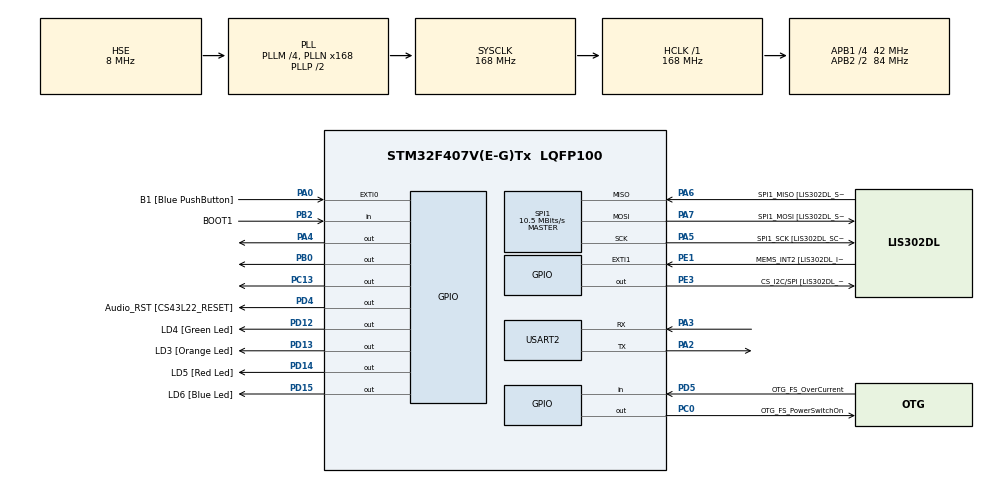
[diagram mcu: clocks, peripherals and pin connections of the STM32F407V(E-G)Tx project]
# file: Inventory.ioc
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Mcu.Family=STM32F4
Mcu.Name=STM32F407V(E-G)Tx
Mcu.Package=LQFP100
NVIC.PriorityGroup=NVIC_PRIORITYGROUP_0
NVIC.USART2_IRQn=true\:0\:0\:false\:false\:true\:true\:true\:true
PA0-WKUP.GPIO_Label=B1 [Blue PushButton]
PA0-WKUP.Signal=GPXTI0
PA10.GPIO_Label=OTG_FS_ID
PA10.GPIO_Mode=GPIO_MODE_AF_PP
PA10.GPIO_PuPd=GPIO_NOPULL
PA10.GPIO_Speed=GPIO_SPEED_FREQ_LOW
PA10.Signal=USB_OTG_FS_ID
PA11.GPIO_Label=OTG_FS_DM
PA11.GPIO_Mode=GPIO_MODE_AF_PP
PA11.GPIO_PuPd=GPIO_NOPULL
PA11.GPIO_Speed=GPIO_SPEED_FREQ_LOW
PA11.Signal=USB_OTG_FS_DM
PA12.GPIO_Label=OTG_FS_DP
PA12.GPIO_Mode=GPIO_MODE_AF_PP
PA12.GPIO_PuPd=GPIO_NOPULL
PA12.GPIO_Speed=GPIO_SPEED_FREQ_LOW
PA12.Signal=USB_OTG_FS_DP
PA13.GPIO_Label=SWDIO
PA13.Mode=Serial_Wire
PA13.Signal=SYS_JTMS-SWDIO
PA14.GPIO_Label=SWCLK
PA14.Mode=Serial_Wire
PA14.Signal=SYS_JTCK-SWCLK
PA2.Mode=Asynchronous
PA2.Signal=USART2_TX
PA3.Mode=Asynchronous
PA3.Signal=USART2_RX
PA4.Signal=GPIO_Output
PA5.GPIO_Label=SPI1_SCK [LIS302DL_SCL/SPC]
PA5.GPIO_Mode=GPIO_MODE_AF_PP
PA5.GPIO_PuPd=GPIO_NOPULL
PA5.GPIO_Speed=GPIO_SPEED_FREQ_LOW
PA5.Mode=Full_Duplex_Master
PA5.Signal=SPI1_SCK
PA6.GPIO_Label=SPI1_MISO [LIS302DL_SDO]
PA6.GPIO_Mode=GPIO_MODE_AF_PP
PA6.GPIO_PuPd=GPIO_NOPULL
PA6.GPIO_Speed=GPIO_SPEED_FREQ_LOW
PA6.Mode=Full_Duplex_Master
PA6.Signal=SPI1_MISO
PA7.GPIO_Label=SPI1_MOSI [LIS302DL_SDA/SDI/SDO]
PA7.GPIO_Mode=GPIO_MODE_AF_PP
PA7.GPIO_PuPd=GPIO_NOPULL
PA7.GPIO_Speed=GPIO_SPEED_FREQ_LOW
PA7.Mode=Full_Duplex_Master
PA7.Signal=SPI1_MOSI
PA9.GPIO_Label=VBUS_FS
PA9.GPIO_Mode=GPIO_MODE_INPUT
PA9.GPIO_PuPd=GPIO_NOPULL
PA9.Signal=USB_OTG_FS_VBUS
PB0.Signal=GPIO_Output
PB10.GPIO_Label=CLK_IN [MP45DT02_CLK]
PB10.GPIO_Mode=GPIO_MODE_AF_PP
PB10.GPIO_PuPd=GPIO_NOPULL
PB10.GPIO_Speed=GPIO_SPEED_FREQ_LOW
PB10.Signal=I2S2_CK
PB2.GPIO_Label=BOOT1
PB2.GPIO_Mode=GPIO_MODE_INPUT
PB2.GPIO_PuPd=GPIO_NOPULL
PB2.Signal=GPIO_Input
PB3.GPIO_Label=SWO
PB3.Signal=SYS_JTDO-SWO
PB6.GPIO_Label=Audio_SCL [CS43L22_SCL]
PB6.GPIO_Mode=GPIO_MODE_AF_OD
PB6.GPIO_PuPd=GPIO_NOPULL
PB6.GPIO_Speed=GPIO_SPEED_FREQ_LOW
PB6.Signal=I2C1_SCL
PB9.GPIO_Label=Audio_SDA [CS43L22_SDA]
PB9.GPIO_Mode=GPIO_MODE_AF_OD
PB9.GPIO_PuPd=GPIO_NOPULL
PB9.GPIO_Speed=GPIO_SPEED_FREQ_LOW
PB9.Signal=I2C1_SDA
PC0.GPIO_Label=OTG_FS_PowerSwitchOn
PC0.GPIO_PuPd=GPIO_NOPULL
PC0.GPIO_Speed=GPIO_SPEED_FREQ_LOW
PC0.PinState=GPIO_PIN_SET
PC0.Signal=GPIO_Output
PC10.GPIO_Label=I2S3_SCK [CS43L22_SCLK]
PC10.GPIO_Mode=GPIO_MODE_AF_PP
PC10.GPIO_PuPd=GPIO_NOPULL
PC10.GPIO_Speed=GPIO_SPEED_FREQ_LOW
PC10.Signal=I2S3_CK
PC12.GPIO_Label=I2S3_SD [CS43L22_SDIN]
PC12.GPIO_Mode=GPIO_MODE_AF_PP
PC12.GPIO_PuPd=GPIO_NOPULL
PC12.GPIO_Speed=GPIO_SPEED_FREQ_LOW
PC12.Signal=I2S3_SD
PC13-ANTI_TAMP.Signal=GPIO_Output
PC14-OSC32_IN.GPIO_Label=PC14-OSC32_IN
PC14-OSC32_IN.Signal=RCC_OSC32_IN
PC15-OSC32_OUT.GPIO_Label=PC15-OSC32_OUT
PC15-OSC32_OUT.Signal=RCC_OSC32_OUT
PC3.GPIO_Label=PDM_OUT [MP45DT02_DOUT]
PC3.GPIO_Mode=GPIO_MODE_AF_PP
PC3.GPIO_PuPd=GPIO_NOPULL
PC3.GPIO_Speed=GPIO_SPEED_FREQ_LOW
PC3.Signal=I2S2_SD
PC7.GPIO_Label=I2S3_MCK [CS43L22_MCLK]
PC7.GPIO_Mode=GPIO_MODE_AF_PP
PC7.GPIO_PuPd=GPIO_NOPULL
PC7.GPIO_Speed=GPIO_SPEED_FREQ_LOW
PC7.Signal=I2S3_MCK
PD12.GPIO_Label=LD4 [Green Led]
PD12.GPIO_PuPd=GPIO_NOPULL
PD12.GPIO_Speed=GPIO_SPEED_FREQ_LOW
PD12.Signal=GPIO_Output
PD13.GPIO_Label=LD3 [Orange Led]
PD13.GPIO_PuPd=GPIO_NOPULL
PD13.GPIO_Speed=GPIO_SPEED_FREQ_LOW
PD13.Signal=GPIO_Output
PD14.GPIO_Label=LD5 [Red Led]
PD14.GPIO_PuPd=GPIO_NOPULL
PD14.GPIO_Speed=GPIO_SPEED_FREQ_LOW
PD14.Signal=GPIO_Output
PD15.GPIO_Label=LD6 [Blue Led]
PD15.GPIO_PuPd=GPIO_NOPULL
PD15.GPIO_Speed=GPIO_SPEED_FREQ_LOW
PD15.Signal=GPIO_Output
PD4.GPIO_Label=Audio_RST [CS43L22_RESET]
PD4.GPIO_PuPd=GPIO_NOPULL
PD4.GPIO_Speed=GPIO_SPEED_FREQ_LOW
PD4.Signal=GPIO_Output
PD5.GPIO_Label=OTG_FS_OverCurrent
PD5.GPIO_Mode=GPIO_MODE_INPUT
PD5.GPIO_PuPd=GPIO_NOPULL
PD5.Signal=GPIO_Input
PE1.GPIO_Label=MEMS_INT2 [LIS302DL_INT2]
PE1.GPIO_ModeDefaultEXTI=GPIO_MODE_EVT_RISING
PE1.GPIO_PuPd=GPIO_NOPULL
PE1.Signal=GPXTI1
PE3.GPIO_Label=CS_I2C/SPI [LIS302DL_CS_I2C/SPI]
PE3.GPIO_PuPd=GPIO_NOPULL
PE3.GPIO_Speed=GPIO_SPEED_FREQ_LOW
PE3.Signal=GPIO_Output
PH0-OSC_IN.GPIO_Label=PH0-OSC_IN
PH0-OSC_IN.Mode=HSE-External-Oscillator
PH0-OSC_IN.Signal=RCC_OSC_IN
PH1-OSC_OUT.GPIO_Label=PH1-OSC_OUT
PH1-OSC_OUT.Mode=HSE-External-Oscillator
PH1-OSC_OUT.Signal=RCC_OSC_OUT
ProjectManager.HeapSize=0x800
ProjectManager.StackSize=0x800
ProjectManager.TargetToolchain=STM32CubeIDE
RCC.48MHZClocksFreq_Value=48000000
RCC.AHBFreq_Value=168000000
RCC.APB1CLKDivider=RCC_HCLK_DIV4
RCC.APB1Freq_Value=42000000
RCC.APB1TimFreq_Value=84000000
RCC.APB2CLKDivider=RCC_HCLK_DIV2
RCC.APB2Freq_Value=84000000
RCC.APB2TimFreq_Value=168000000
RCC.CortexFreq_Value=168000000
RCC.HCLKFreq_Value=168000000
RCC.HSE_VALUE=8000000
RCC.HSI_VALUE=16000000
RCC.LSE_VALUE=32768
RCC.PLLM=4
RCC.PLLN=168
RCC.PLLP=2
RCC.PLLQ=7
RCC.PLLSourceVirtual=RCC_PLLSOURCE_HSE
RCC.SYSCLKFreq_VALUE=168000000
RCC.SYSCLKSource=RCC_SYSCLKSOURCE_PLLCLK
RCC.VCOOutputFreq_Value=336000000
SPI1.BaudRatePrescaler=SPI_BAUDRATEPRESCALER_8
SPI1.CalculateBaudRate=10.5 MBits/s
SPI1.Direction=SPI_DIRECTION_2LINES
SPI1.Mode=SPI_MODE_MASTER
SPI1.VirtualType=VM_MASTER
STMicroelectronics.X-CUBE-AI.8.1.0.ActivationBufferSizeList=2488224
STMicroelectronics.X-CUBE-AI.8.1.0.ActivationBuffers=(ai_handle) 0x00000000
STMicroelectronics.X-CUBE-AI.8.1.0.ActivationPragmas=AI_CUSTOM
STMicroelectronics.X-CUBE-AI.8.1.0.HeapSize=0x800
STMicroelectronics.X-CUBE-AI.8.1.0.InternalRamActivationBufferMaxSize=AI_NETWORK_9_DATA_ACTIVATIONS_SIZE
STMicroelectronics.X-CUBE-AI.8.1.0.LatestDirectoryUsed-e215b0f68a62c3eeb1ee8877ed58282e5802af02ffe05f54a25cac139fafb503=C\:\\Users\\user\\Desktop\\IOT
STMicroelectronics.X-CUBE-AI.8.1.0.MaximumNumberOfInputLayer=1
STMicroelectronics.X-CUBE-AI.8.1.0.MaximumNumberOfOutputLayer=1
STMicroelectronics.X-CUBE-AI.8.1.0.MaximumSizeOfInputLayer=1
STMicroelectronics.X-CUBE-AI.8.1.0.MaximumSizeOfOutputLayer=1
STMicroelectronics.X-CUBE-AI.8.1.0.ModelActualCompression-e215b0f68a62c3eeb1ee8877ed58282e5802af02ffe05f54a25cac139fafb503=0.0
STMicroelectronics.X-CUBE-AI.8.1.0.ModelCompression-e215b0f68a62c3eeb1ee8877ed58282e5802af02ffe05f54a25cac139fafb503=None
STMicroelectronics.X-CUBE-AI.8.1.0.ModelFlashOccupation-e215b0f68a62c3eeb1ee8877ed58282e5802af02ffe05f54a25cac139fafb503=2128442
STMicroelectronics.X-CUBE-AI.8.1.0.ModelHashList=e215b0f68a62c3eeb1ee8877ed58282e5802af02ffe05f54a25cac139fafb503
STMicroelectronics.X-CUBE-AI.8.1.0.ModelKind-e215b0f68a62c3eeb1ee8877ed58282e5802af02ffe05f54a25cac139fafb503=KERAS
STMicroelectronics.X-CUBE-AI.8.1.0.ModelMacc-e215b0f68a62c3eeb1ee8877ed58282e5802af02ffe05f54a25cac139fafb503=63536066
STMicroelectronics.X-CUBE-AI.8.1.0.ModelName-e215b0f68a62c3eeb1ee8877ed58282e5802af02ffe05f54a25cac139fafb503=network_9
STMicroelectronics.X-CUBE-AI.8.1.0.ModelNameList=network_9
STMicroelectronics.X-CUBE-AI.8.1.0.ModelRamOccupation-e215b0f68a62c3eeb1ee8877ed58282e5802af02ffe05f54a25cac139fafb503=2488224
STMicroelectronics.X-CUBE-AI.8.1.0.ModelStructureFile-e215b0f68a62c3eeb1ee8877ed58282e5802af02ffe05f54a25cac139fafb503=C\:\\Users\\user\\Desktop\\IOT\\keras_model.h5
STMicroelectronics.X-CUBE-AI.8.1.0.ModelType-e215b0f68a62c3eeb1ee8877ed58282e5802af02ffe05f54a25cac139fafb503=Saved model
STMicroelectronics.X-CUBE-AI.8.1.0.ReadyForCodeGeneration=true
STMicroelectronics.X-CUBE-AI.8.1.0.StackSize=0x800
STMicroelectronics.X-CUBE-AI.8.1.0.WorkingBufferStartAddrList=0xFFFFFFFF
STMicroelectronics.X-CUBE-AI.8.1.0.XAaCUBEAaAICcArtificialOoIntelligenceJjCore=true
STMicroelectronics.X-CUBE-AI.8.1.0.copyWeightToRam=false
STMicroelectronics.X-CUBE-AI.8.1.0.copyWeightToRam-e215b0f68a62c3eeb1ee8877ed58282e5802af02ffe05f54a25cac139fafb503=false
STMicroelectronics.X-CUBE-AI.8.1.0.customLayerConfigEnabled=false
STMicroelectronics.X-CUBE-AI.8.1.0.customLayerConfigEnabled-e215b0f68a62c3eeb1ee8877ed58282e5802af02ffe05f54a25cac139fafb503=false
STMicroelectronics.X-CUBE-AI.8.1.0.memoryPool0driver-e215b0f68a62c3eeb1ee8877ed58282e5802af02ffe05f54a25cac139fafb503=RAM
STMicroelectronics.X-CUBE-AI.8.1.0.memoryPool0id-e215b0f68a62c3eeb1ee8877ed58282e5802af02ffe05f54a25cac139fafb503=-1
STMicroelectronics.X-CUBE-AI.8.1.0.memoryPool0max-e215b0f68a62c3eeb1ee8877ed58282e5802af02ffe05f54a25cac139fafb503=112
STMicroelectronics.X-CUBE-AI.8.1.0.memoryPool0name-e215b0f68a62c3eeb1ee8877ed58282e5802af02ffe05f54a25cac139fafb503=pool1
STMicroelectronics.X-CUBE-AI.8.1.0.memoryPool0size-e215b0f68a62c3eeb1ee8877ed58282e5802af02ffe05f54a25cac139fafb503=112
STMicroelectronics.X-CUBE-AI.8.1.0.memoryPool0start-e215b0f68a62c3eeb1ee8877ed58282e5802af02ffe05f54a25cac139fafb503=Auto
STMicroelectronics.X-CUBE-AI.8.1.0.memoryPool0used-e215b0f68a62c3eeb1ee8877ed58282e5802af02ffe05f54a25cac139fafb503=0.0
STMicroelectronics.X-CUBE-AI.8.1.0.memoryPool1driver-e215b0f68a62c3eeb1ee8877ed58282e5802af02ffe05f54a25cac139fafb503=RAM2
STMicroelectronics.X-CUBE-AI.8.1.0.memoryPool1id-e215b0f68a62c3eeb1ee8877ed58282e5802af02ffe05f54a25cac139fafb503=-1
STMicroelectronics.X-CUBE-AI.8.1.0.memoryPool1max-e215b0f68a62c3eeb1ee8877ed58282e5802af02ffe05f54a25cac139fafb503=16
STMicroelectronics.X-CUBE-AI.8.1.0.memoryPool1name-e215b0f68a62c3eeb1ee8877ed58282e5802af02ffe05f54a25cac139fafb503=pool2
STMicroelectronics.X-CUBE-AI.8.1.0.memoryPool1size-e215b0f68a62c3eeb1ee8877ed58282e5802af02ffe05f54a25cac139fafb503=16
STMicroelectronics.X-CUBE-AI.8.1.0.memoryPool1start-e215b0f68a62c3eeb1ee8877ed58282e5802af02ffe05f54a25cac139fafb503=Auto
STMicroelectronics.X-CUBE-AI.8.1.0.memoryPool1used-e215b0f68a62c3eeb1ee8877ed58282e5802af02ffe05f54a25cac139fafb503=0.0
STMicroelectronics.X-CUBE-AI.8.1.0.memoryPool2driver-e215b0f68a62c3eeb1ee8877ed58282e5802af02ffe05f54a25cac139fafb503=CCMRAM
STMicroelectronics.X-CUBE-AI.8.1.0.memoryPool2id-e215b0f68a62c3eeb1ee8877ed58282e5802af02ffe05f54a25cac139fafb503=-1
STMicroelectronics.X-CUBE-AI.8.1.0.memoryPool2max-e215b0f68a62c3eeb1ee8877ed58282e5802af02ffe05f54a25cac139fafb503=64
STMicroelectronics.X-CUBE-AI.8.1.0.memoryPool2name-e215b0f68a62c3eeb1ee8877ed58282e5802af02ffe05f54a25cac139fafb503=pool3
STMicroelectronics.X-CUBE-AI.8.1.0.memoryPool2size-e215b0f68a62c3eeb1ee8877ed58282e5802af02ffe05f54a25cac139fafb503=64
STMicroelectronics.X-CUBE-AI.8.1.0.memoryPool2start-e215b0f68a62c3eeb1ee8877ed58282e5802af02ffe05f54a25cac139fafb503=Auto
STMicroelectronics.X-CUBE-AI.8.1.0.memoryPool2used-e215b0f68a62c3eeb1ee8877ed58282e5802af02ffe05f54a25cac139fafb503=0.0
STMicroelectronics.X-CUBE-AI.8.1.0.memoryPool3driver-e215b0f68a62c3eeb1ee8877ed58282e5802af02ffe05f54a25cac139fafb503=Custom
STMicroelectronics.X-CUBE-AI.8.1.0.memoryPool3id-e215b0f68a62c3eeb1ee8877ed58282e5802af02ffe05f54a25cac139fafb503=0
STMicroelectronics.X-CUBE-AI.8.1.0.memoryPool3max-e215b0f68a62c3eeb1ee8877ed58282e5802af02ffe05f54a25cac139fafb503=2147483647
STMicroelectronics.X-CUBE-AI.8.1.0.memoryPool3name-e215b0f68a62c3eeb1ee8877ed58282e5802af02ffe05f54a25cac139fafb503=pool4
STMicroelectronics.X-CUBE-AI.8.1.0.memoryPool3size-e215b0f68a62c3eeb1ee8877ed58282e5802af02ffe05f54a25cac139fafb503=0
STMicroelectronics.X-CUBE-AI.8.1.0.memoryPool3start-e215b0f68a62c3eeb1ee8877ed58282e5802af02ffe05f54a25cac139fafb503=0x00000000
STMicroelectronics.X-CUBE-AI.8.1.0.memoryPool3used-e215b0f68a62c3eeb1ee8877ed58282e5802af02ffe05f54a25cac139fafb503=2458816.0
STMicroelectronics.X-CUBE-AI.8.1.0.noOnnxIoTranspose=false
STMicroelectronics.X-CUBE-AI.8.1.0.noOnnxIoTranspose-e215b0f68a62c3eeb1ee8877ed58282e5802af02ffe05f54a25cac139fafb503=false
STMicroelectronics.X-CUBE-AI.8.1.0.splitWeigths-e215b0f68a62c3eeb1ee8877ed58282e5802af02ffe05f54a25cac139fafb503=true
STMicroelectronics.X-CUBE-AI.8.1.0.useInputAllocation=true
STMicroelectronics.X-CUBE-AI.8.1.0.useInputAllocation-e215b0f68a62c3eeb1ee8877ed58282e5802af02ffe05f54a25cac139fafb503=true
STMicroelectronics.X-CUBE-AI.8.1.0.useOutputAllocation=true
STMicroelectronics.X-CUBE-AI.8.1.0.useOutputAllocation-e215b0f68a62c3eeb1ee8877ed58282e5802af02ffe05f54a25cac139fafb503=true
USART2.VirtualMode=VM_ASYNC
VP_CRC_VS_CRC.Mode=CRC_Activate
VP_STMicroelectronics.X-CUBE-AI_VS_ArtificialOoIntelligenceJjXAaCUBEAaAI_8.1.0_8.1.0.Mode=ArtificialOoIntelligenceJjXAaCUBEAaAI
board=STM32F407G-DISC1

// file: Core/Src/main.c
/* USER CODE BEGIN Header */
/**
  ******************************************************************************
  * @file           : main.c
  * @brief          : Main program body
  ******************************************************************************
  * @attention
  *
  * Copyright (c) 2024 STMicroelectronics.
  * All rights reserved.
  *
  * This software is licensed under terms that can be found in the LICENSE file
  * in the root directory of this software component.
  * If no LICENSE file comes with this software, it is provided AS-IS.
  *
  ******************************************************************************
  */
/* USER CODE END Header */
#include "main.h"
#include "stdlib.h"
#include "ai_platform.h"
#include "ai_datatypes_defines.h"
#include "network_9_data_params.h"
#include "network_9_data.h"
#include "network_9_config.h"
#include "network_9.h"

/* USER CODE BEGIN Includes */
#include "rc522.h"
#include "string.h"
#include "stdio.h"
#include "stdint.h"
#include "errno.h"

/* USER CODE END Includes */

CRC_HandleTypeDef hcrc;

SPI_HandleTypeDef hspi1;

UART_HandleTypeDef huart2;

/* USER CODE BEGIN PV */
#define UNREAL_RFID_DATA "ABCDE"
#define RFID_DATA_SIZE 5
#define CLASSIFICATION_RESULT_SIZE 20
char out_data[CLASSIFICATION_RESULT_SIZE];
ai_handle network_9 = AI_HANDLE_NULL;
ai_buffer ai_input[AI_NETWORK_9_IN_NUM]; // Declare ai_input
ai_buffer ai_output[AI_NETWORK_9_OUT_NUM]; // Declare ai_output
void SystemClock_Config(void);
static void MX_GPIO_Init(void);
static void MX_CRC_Init(void);
static void MX_SPI1_Init(void);
static void MX_USART2_UART_Init(void);
void send_data_to_nodemcu(uint8_t* rfid_data, char* classification_results);
void classify_image(const float* input_image_data, ai_handle network_handle);
float* read_image_file(const char* filename);

int main(void) {
    uint8_t rfid_data[RFID_DATA_SIZE];
    char buf[50];
    int buf_len = 0;
    ai_error ai_err;
    ai_i32 nbatch;
    float y_val;
    HAL_Init();
    SystemClock_Config();
    MX_GPIO_Init();
    MX_CRC_Init();
    MX_SPI1_Init();
    MX_USART2_UART_Init();
    uint8_t buffer_uart[] = "Hello world";
    // Chunk of memory used to hold intermediate values for neural network
    AI_ALIGNED(4) ai_u8 activations[AI_NETWORK_9_DATA_ACTIVATIONS_SIZE];

    // Buffers used to store input and output tensors
    AI_ALIGNED(4) ai_i8 in_data[AI_NETWORK_9_IN_1_SIZE_BYTES];
    AI_ALIGNED(4) ai_i8 out_data[AI_NETWORK_9_OUT_1_SIZE_BYTES];

    ai_network_params ai_params = {
        .params = {}
    };

    // Initialize ai_input and ai_output
    ai_input[0].data = AI_HANDLE_PTR(in_data);
    ai_output[0].data = AI_HANDLE_PTR(out_data);

    // Greetings!
    buf_len = sprintf(buf, "\r\n\r\nSTM32 X-Cube-AI test\r\n");
    HAL_UART_Transmit(&huart2, (uint8_t *)buf, buf_len, 100);
    HAL_UART_Transmit(&huart2, buffer_uart, sizeof(buffer_uart), 100);
    ai_error err = ai_network_9_create(&network_9, AI_NETWORK_9_DATA_CONFIG);
    if (err.type != AI_ERROR_NONE) {
        printf("Error: could not create NN instance\n");
        return 1;
    }

    if (!ai_network_9_init(network_9, &ai_params)) {
        printf("Error: could not initialize NN\n");
        return 1;
    }

    while (1) {
        uint8_t unreal_rfid_data[RFID_DATA_SIZE] = UNREAL_RFID_DATA;
        // Declare uart_frame variable
            uint8_t uart_frame[RFID_DATA_SIZE + CLASSIFICATION_RESULT_SIZE + 2];
        const char* image_filename = "C:\\Users\\user\\Desktop\\IOT\\Newvideos\\00000\\frame_0.jpg"; // Change this to the path of your image file
        float* input_image_data = read_image_file(image_filename);
        if (!input_image_data) {
            printf("Failed to read image file\n");
            return 1;
        }

        // Set input data for neural network
        memcpy(in_data, input_image_data, AI_NETWORK_9_IN_1_SIZE_BYTES);

        // Debug message before UART transmission
            printf("Transmitting data over UART...\n");

            // Transmit data over UART
            HAL_UART_Transmit(&huart2, uart_frame, sizeof(uart_frame), HAL_MAX_DELAY);

            // Debug message after UART transmission
            printf("Data transmitted over UART\n");

        free(input_image_data);

        // Perform inference
        nbatch = ai_network_9_run(network_9, &ai_input[0], &ai_output[0]);
        if (nbatch != 1) {
            printf("Error: could not run inference\r\n");
        } else {
            // Read output (predicted y) of neural network
            y_val = ((float *)out_data)[0];

            // Print output of neural network along with inference time (microseconds)
            buf_len = sprintf(buf, "Classification result: %f\r\n", y_val);
            HAL_UART_Transmit(&huart2, (uint8_t *)buf, buf_len, 100);
        }

        send_data_to_nodemcu(unreal_rfid_data, out_data); // Use out_data here

        HAL_Delay(100); // Adjust delay as needed
    }
    return 0;
}

void send_data_to_nodemcu(uint8_t* rfid_data, char* classification_results) {
    uint8_t uart_frame[RFID_DATA_SIZE + CLASSIFICATION_RESULT_SIZE + 2];
    uart_frame[0] = 0xAA; // Start of Frame marker
    memcpy(&uart_frame[1], rfid_data, RFID_DATA_SIZE);
    uart_frame[RFID_DATA_SIZE + 1 + CLASSIFICATION_RESULT_SIZE] = 0x55; // End of Frame marker

    HAL_UART_Transmit(&huart2, uart_frame, sizeof(uart_frame), HAL_MAX_DELAY);
}

float* read_image_file(const char* filename) {
    FILE* file = fopen(filename, "rb");
    if (!file) {
        printf("Error opening file: %s\n", strerror(errno));
        return NULL;
    }

    fseek(file, 0, SEEK_END);
    long file_size = ftell(file);
    fseek(file, 0, SEEK_SET);

    float* image_data = (float*)malloc(file_size);
    if (!image_data) {
        fclose(file);
        printf("Error allocating memory\n");
        return NULL;
    }

    size_t bytes_read = fread(image_data, 1, file_size, file);
    fclose(file);

    if (bytes_read != file_size) {
        free(image_data);
        printf("Error reading file\n");
        return NULL;
    }

    return image_data;
}
void SystemClock_Config(void)
{
  RCC_OscInitTypeDef RCC_OscInitStruct = {0};
  RCC_ClkInitTypeDef RCC_ClkInitStruct = {0};

  /** Configure the main internal regulator output voltage
  */
  __HAL_RCC_PWR_CLK_ENABLE();
  __HAL_PWR_VOLTAGESCALING_CONFIG(PWR_REGULATOR_VOLTAGE_SCALE1);

  /** Initializes the RCC Oscillators according to the specified parameters
  * in the RCC_OscInitTypeDef structure.
  */
  RCC_OscInitStruct.OscillatorType = RCC_OSCILLATORTYPE_HSE;
  RCC_OscInitStruct.HSEState = RCC_HSE_ON;
  RCC_OscInitStruct.PLL.PLLState = RCC_PLL_ON;
  RCC_OscInitStruct.PLL.PLLSource = RCC_PLLSOURCE_HSE;
  RCC_OscInitStruct.PLL.PLLM = 4;
  RCC_OscInitStruct.PLL.PLLN = 168;
  RCC_OscInitStruct.PLL.PLLP = 2;
  RCC_OscInitStruct.PLL.PLLQ = 7;
  if (HAL_RCC_OscConfig(&RCC_OscInitStruct) != HAL_OK)
  {
    Error_Handler();
  }

  /** Initializes the CPU, AHB and APB buses clocks
  */
  RCC_ClkInitStruct.ClockType = RCC_CLOCKTYPE_HCLK|RCC_CLOCKTYPE_SYSCLK
                              |RCC_CLOCKTYPE_PCLK1|RCC_CLOCKTYPE_PCLK2;
  RCC_ClkInitStruct.SYSCLKSource = RCC_SYSCLKSOURCE_PLLCLK;
  RCC_ClkInitStruct.AHBCLKDivider = RCC_SYSCLK_DIV1;
  RCC_ClkInitStruct.APB1CLKDivider = RCC_HCLK_DIV4;
  RCC_ClkInitStruct.APB2CLKDivider = RCC_HCLK_DIV2;

  if (HAL_RCC_ClockConfig(&RCC_ClkInitStruct, FLASH_LATENCY_5) != HAL_OK)
  {
    Error_Handler();
  }
}

static void MX_CRC_Init(void)
{

  hcrc.Instance = CRC;
  if (HAL_CRC_Init(&hcrc) != HAL_OK)
  {
    Error_Handler();
  }

}

static void MX_SPI1_Init(void)
{

  /* SPI1 parameter configuration*/
  hspi1.Instance = SPI1;
  hspi1.Init.Mode = SPI_MODE_MASTER;
  hspi1.Init.Direction = SPI_DIRECTION_2LINES;
  hspi1.Init.DataSize = SPI_DATASIZE_8BIT;
  hspi1.Init.CLKPolarity = SPI_POLARITY_LOW;
  hspi1.Init.CLKPhase = SPI_PHASE_1EDGE;
  hspi1.Init.NSS = SPI_NSS_SOFT;
  hspi1.Init.BaudRatePrescaler = SPI_BAUDRATEPRESCALER_8;
  hspi1.Init.FirstBit = SPI_FIRSTBIT_MSB;
  hspi1.Init.TIMode = SPI_TIMODE_DISABLE;
  hspi1.Init.CRCCalculation = SPI_CRCCALCULATION_DISABLE;
  hspi1.Init.CRCPolynomial = 10;
  if (HAL_SPI_Init(&hspi1) != HAL_OK)
  {
    Error_Handler();
  }

}

static void MX_USART2_UART_Init(void)
{

  huart2.Instance = USART2;
  huart2.Init.BaudRate = 115200;
  huart2.Init.WordLength = UART_WORDLENGTH_8B;
  huart2.Init.StopBits = UART_STOPBITS_1;
  huart2.Init.Parity = UART_PARITY_NONE;
  huart2.Init.Mode = UART_MODE_TX_RX;
  huart2.Init.HwFlowCtl = UART_HWCONTROL_NONE;
  huart2.Init.OverSampling = UART_OVERSAMPLING_16;
  if (HAL_UART_Init(&huart2) != HAL_OK)
  {
    Error_Handler();
  }

}

static void MX_GPIO_Init(void)
{
  GPIO_InitTypeDef GPIO_InitStruct = {0};

  /* GPIO Ports Clock Enable */
  __HAL_RCC_GPIOE_CLK_ENABLE();
  __HAL_RCC_GPIOC_CLK_ENABLE();
  __HAL_RCC_GPIOH_CLK_ENABLE();
  __HAL_RCC_GPIOA_CLK_ENABLE();
  __HAL_RCC_GPIOB_CLK_ENABLE();
  __HAL_RCC_GPIOD_CLK_ENABLE();

  /*Configure GPIO pin Output Level */
  HAL_GPIO_WritePin(CS_I2C_SPI_GPIO_Port, CS_I2C_SPI_Pin, GPIO_PIN_RESET);

  /*Configure GPIO pin Output Level */
  HAL_GPIO_WritePin(GPIOC, GPIO_PIN_13, GPIO_PIN_RESET);

  /*Configure GPIO pin Output Level */
  HAL_GPIO_WritePin(OTG_FS_PowerSwitchOn_GPIO_Port, OTG_FS_PowerSwitchOn_Pin, GPIO_PIN_SET);

  /*Configure GPIO pin Output Level */
  HAL_GPIO_WritePin(GPIOA, GPIO_PIN_4, GPIO_PIN_RESET);

  /*Configure GPIO pin Output Level */
  HAL_GPIO_WritePin(GPIOB, GPIO_PIN_0, GPIO_PIN_RESET);

  /*Configure GPIO pin Output Level */
  HAL_GPIO_WritePin(GPIOD, LD4_Pin|LD3_Pin|LD5_Pin|LD6_Pin
                          |Audio_RST_Pin, GPIO_PIN_RESET);

  /*Configure GPIO pin : CS_I2C_SPI_Pin */
  GPIO_InitStruct.Pin = CS_I2C_SPI_Pin;
  GPIO_InitStruct.Mode = GPIO_MODE_OUTPUT_PP;
  GPIO_InitStruct.Pull = GPIO_NOPULL;
  GPIO_InitStruct.Speed = GPIO_SPEED_FREQ_LOW;
  HAL_GPIO_Init(CS_I2C_SPI_GPIO_Port, &GPIO_InitStruct);

  /*Configure GPIO pins : PC13 OTG_FS_PowerSwitchOn_Pin */
  GPIO_InitStruct.Pin = GPIO_PIN_13|OTG_FS_PowerSwitchOn_Pin;
  GPIO_InitStruct.Mode = GPIO_MODE_OUTPUT_PP;
  GPIO_InitStruct.Pull = GPIO_NOPULL;
  GPIO_InitStruct.Speed = GPIO_SPEED_FREQ_LOW;
  HAL_GPIO_Init(GPIOC, &GPIO_InitStruct);

  /*Configure GPIO pin : PDM_OUT_Pin */
  GPIO_InitStruct.Pin = PDM_OUT_Pin;
  GPIO_InitStruct.Mode = GPIO_MODE_AF_PP;
  GPIO_InitStruct.Pull = GPIO_NOPULL;
  GPIO_InitStruct.Speed = GPIO_SPEED_FREQ_LOW;
  GPIO_InitStruct.Alternate = GPIO_AF5_SPI2;
  HAL_GPIO_Init(PDM_OUT_GPIO_Port, &GPIO_InitStruct);

  /*Configure GPIO pin : B1_Pin */
  GPIO_InitStruct.Pin = B1_Pin;
  GPIO_InitStruct.Mode = GPIO_MODE_IT_RISING;
  GPIO_InitStruct.Pull = GPIO_NOPULL;
  HAL_GPIO_Init(B1_GPIO_Port, &GPIO_InitStruct);

  /*Configure GPIO pin : PA4 */
  GPIO_InitStruct.Pin = GPIO_PIN_4;
  GPIO_InitStruct.Mode = GPIO_MODE_OUTPUT_PP;
  GPIO_InitStruct.Pull = GPIO_NOPULL;
  GPIO_InitStruct.Speed = GPIO_SPEED_FREQ_LOW;
  HAL_GPIO_Init(GPIOA, &GPIO_InitStruct);

  /*Configure GPIO pin : PB0 */
  GPIO_InitStruct.Pin = GPIO_PIN_0;
  GPIO_InitStruct.Mode = GPIO_MODE_OUTPUT_PP;
  GPIO_InitStruct.Pull = GPIO_NOPULL;
  GPIO_InitStruct.Speed = GPIO_SPEED_FREQ_LOW;
  HAL_GPIO_Init(GPIOB, &GPIO_InitStruct);

  /*Configure GPIO pin : BOOT1_Pin */
  GPIO_InitStruct.Pin = BOOT1_Pin;
  GPIO_InitStruct.Mode = GPIO_MODE_INPUT;
  GPIO_InitStruct.Pull = GPIO_NOPULL;
  HAL_GPIO_Init(BOOT1_GPIO_Port, &GPIO_InitStruct);

  /*Configure GPIO pin : CLK_IN_Pin */
  GPIO_InitStruct.Pin = CLK_IN_Pin;
  GPIO_InitStruct.Mode = GPIO_MODE_AF_PP;
  GPIO_InitStruct.Pull = GPIO_NOPULL;
  GPIO_InitStruct.Speed = GPIO_SPEED_FREQ_LOW;
  GPIO_InitStruct.Alternate = GPIO_AF5_SPI2;
  HAL_GPIO_Init(CLK_IN_GPIO_Port, &GPIO_InitStruct);

  /*Configure GPIO pins : LD4_Pin LD3_Pin LD5_Pin LD6_Pin
                           Audio_RST_Pin */
  GPIO_InitStruct.Pin = LD4_Pin|LD3_Pin|LD5_Pin|LD6_Pin
                          |Audio_RST_Pin;
  GPIO_InitStruct.Mode = GPIO_MODE_OUTPUT_PP;
  GPIO_InitStruct.Pull = GPIO_NOPULL;
  GPIO_InitStruct.Speed = GPIO_SPEED_FREQ_LOW;
  HAL_GPIO_Init(GPIOD, &GPIO_InitStruct);

  /*Configure GPIO pins : I2S3_MCK_Pin I2S3_SCK_Pin I2S3_SD_Pin */
  GPIO_InitStruct.Pin = I2S3_MCK_Pin|I2S3_SCK_Pin|I2S3_SD_Pin;
  GPIO_InitStruct.Mode = GPIO_MODE_AF_PP;
  GPIO_InitStruct.Pull = GPIO_NOPULL;
  GPIO_InitStruct.Speed = GPIO_SPEED_FREQ_LOW;
  GPIO_InitStruct.Alternate = GPIO_AF6_SPI3;
  HAL_GPIO_Init(GPIOC, &GPIO_InitStruct);

  /*Configure GPIO pin : VBUS_FS_Pin */
  GPIO_InitStruct.Pin = VBUS_FS_Pin;
  GPIO_InitStruct.Mode = GPIO_MODE_INPUT;
  GPIO_InitStruct.Pull = GPIO_NOPULL;
  HAL_GPIO_Init(VBUS_FS_GPIO_Port, &GPIO_InitStruct);

  /*Configure GPIO pins : OTG_FS_ID_Pin OTG_FS_DM_Pin OTG_FS_DP_Pin */
  GPIO_InitStruct.Pin = OTG_FS_ID_Pin|OTG_FS_DM_Pin|OTG_FS_DP_Pin;
  GPIO_InitStruct.Mode = GPIO_MODE_AF_PP;
  GPIO_InitStruct.Pull = GPIO_NOPULL;
  GPIO_InitStruct.Speed = GPIO_SPEED_FREQ_LOW;
  GPIO_InitStruct.Alternate = GPIO_AF10_OTG_FS;
  HAL_GPIO_Init(GPIOA, &GPIO_InitStruct);

  /*Configure GPIO pin : OTG_FS_OverCurrent_Pin */
  GPIO_InitStruct.Pin = OTG_FS_OverCurrent_Pin;
  GPIO_InitStruct.Mode = GPIO_MODE_INPUT;
  GPIO_InitStruct.Pull = GPIO_NOPULL;
  HAL_GPIO_Init(OTG_FS_OverCurrent_GPIO_Port, &GPIO_InitStruct);

  /*Configure GPIO pins : Audio_SCL_Pin Audio_SDA_Pin */
  GPIO_InitStruct.Pin = Audio_SCL_Pin|Audio_SDA_Pin;
  GPIO_InitStruct.Mode = GPIO_MODE_AF_OD;
  GPIO_InitStruct.Pull = GPIO_NOPULL;
  GPIO_InitStruct.Speed = GPIO_SPEED_FREQ_LOW;
  GPIO_InitStruct.Alternate = GPIO_AF4_I2C1;
  HAL_GPIO_Init(GPIOB, &GPIO_InitStruct);

  /*Configure GPIO pin : MEMS_INT2_Pin */
  GPIO_InitStruct.Pin = MEMS_INT2_Pin;
  GPIO_InitStruct.Mode = GPIO_MODE_EVT_RISING;
  GPIO_InitStruct.Pull = GPIO_NOPULL;
  HAL_GPIO_Init(MEMS_INT2_GPIO_Port, &GPIO_InitStruct);

}

void Error_Handler(void)
{
  __disable_irq();
  while (1)
  {
  }
}
